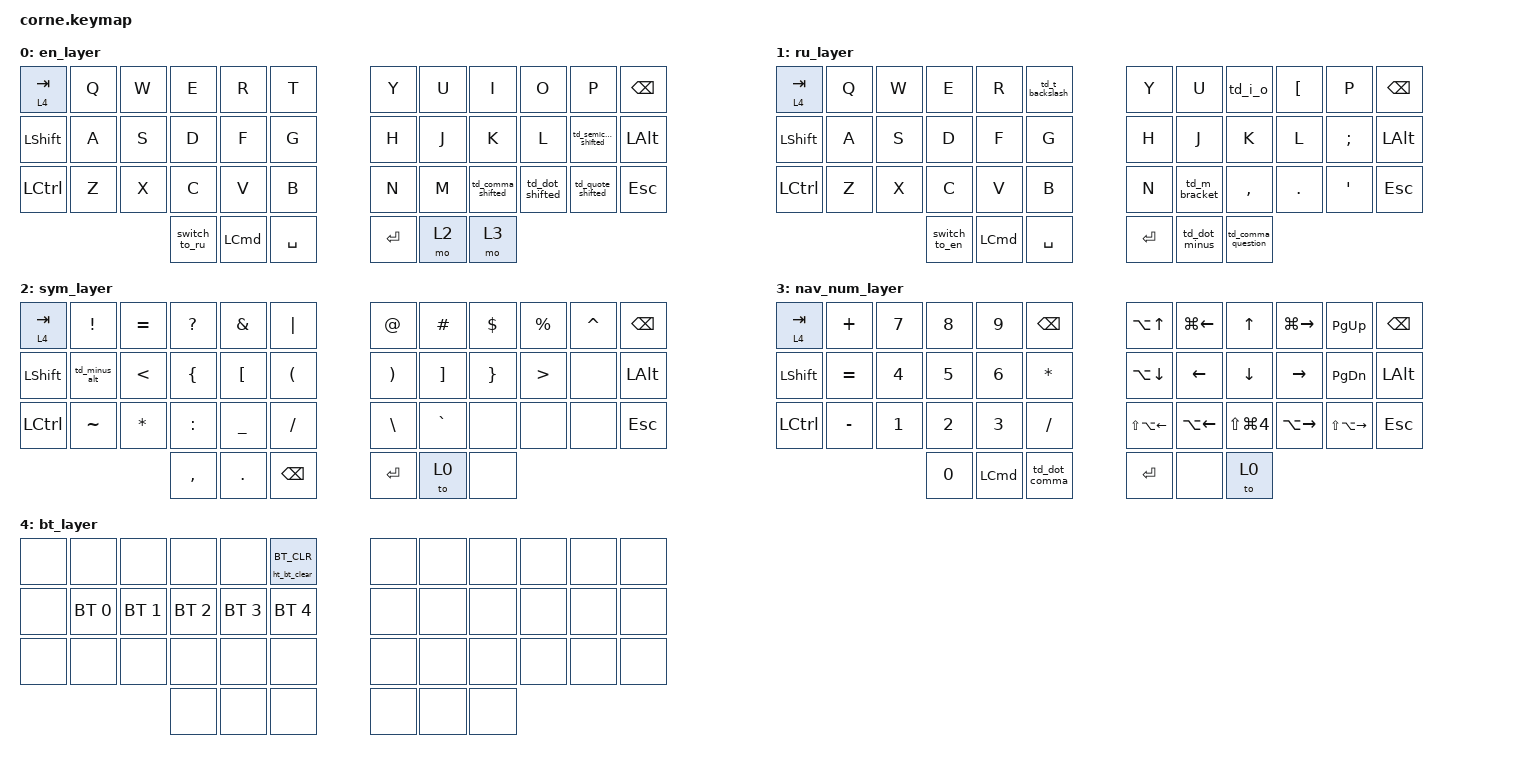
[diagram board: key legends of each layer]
/*
 * Copyright (c) 2020 The ZMK Contributors
 *
 * SPDX-License-Identifier: MIT
 */

#include <behaviors.dtsi>
#include <dt-bindings/zmk/bt.h>
#include <dt-bindings/zmk/keys.h>

/ {
    macros {
        switch_to_ru: switch_to_ru {
            compatible = "zmk,behavior-macro";
            #binding-cells = <0>;
            bindings = <&kp F18 &to 1>;
            label = "SWITCH_TO_RU";
        };

        switch_to_en: switch_to_en {
            compatible = "zmk,behavior-macro";
            #binding-cells = <0>;
            bindings = <&kp F17 &to 0>;
            label = "SWITCH_TO_EN";
        };
    };

    behaviors {
        td_m_bracket: td_m_bracket {
            compatible = "zmk,behavior-tap-dance";
            #binding-cells = <0>;
            bindings = <&kp M>, <&kp RIGHT_BRACKET>;
        };

        td_i_o: td_i_o {
            compatible = "zmk,behavior-tap-dance";
            #binding-cells = <0>;
            bindings = <&kp I>, <&kp O>;
        };

        td_t_backslash: td_t_backslash {
            compatible = "zmk,behavior-tap-dance";
            #binding-cells = <0>;
            bindings = <&kp T>, <&kp BACKSLASH>;
        };

        ht_tab_layer: ht_tab_layer {
            compatible = "zmk,behavior-hold-tap";
            bindings = <&mo>, <&kp>;

            #binding-cells = <2>;
            tapping-term-ms = <200>;
            flavor = "tap-preferred";
        };

        td_dot_comma: td_dot_comma {
            compatible = "zmk,behavior-tap-dance";
            #binding-cells = <0>;
            bindings = <&kp DOT>, <&kp COMMA>;
        };

        td_comma_shifted: td_comma_shifted {
            compatible = "zmk,behavior-tap-dance";
            #binding-cells = <0>;
            bindings = <&kp COMMA>, <&kp LS(COMMA)>;
        };

        td_dot_shifted: td_dot_shifted {
            compatible = "zmk,behavior-tap-dance";
            #binding-cells = <0>;
            bindings = <&kp DOT>, <&kp LS(DOT)>;
        };

        td_semicolon_shifted: td_semicolon_shifted {
            compatible = "zmk,behavior-tap-dance";
            #binding-cells = <0>;
            bindings = <&kp SEMI>, <&kp LS(SEMICOLON)>;
        };

        td_quote_shifted: td_quote_shifted {
            compatible = "zmk,behavior-tap-dance";
            #binding-cells = <0>;
            bindings = <&kp SINGLE_QUOTE>, <&kp LS(SINGLE_QUOTE)>;
        };

        ht_bt_clear: ht_bt_clear {
            compatible = "zmk,behavior-hold-tap";
            bindings = <&bt>, <&none>;

            #binding-cells = <2>;
            tapping-term-ms = <500>;
            flavor = "hold-preferred";
        };

        td_minus_alt: td_minus_alt {
            compatible = "zmk,behavior-tap-dance";
            #binding-cells = <0>;
            bindings = <&kp KP_MINUS>, <&kp LA(MINUS)>;
        };

        td_dot_minus: td_dot_minus {
            compatible = "zmk,behavior-tap-dance";
            #binding-cells = <0>;
            bindings = <&kp KP_DOT>, <&kp MINUS>;

            label = "TD_DOT_MINUS";
        };

        td_comma_question: td_comma_question {
            compatible = "zmk,behavior-tap-dance";
            #binding-cells = <0>;
            bindings = <&kp LS(KP_DOT)>, <&kp QUESTION>;

            label = "TD_COMMA_QUESTION";
        };
    };

    keymap {
        compatible = "zmk,keymap";

        en_layer {
            bindings = <
&ht_tab_layer 4 TAB  &kp Q  &kp W  &kp E          &kp R             &kp T        &kp Y      &kp U  &kp I              &kp O            &kp P                  &kp BSPC
&kp LEFT_SHIFT       &kp A  &kp S  &kp D          &kp F             &kp G        &kp H      &kp J  &kp K              &kp L            &td_semicolon_shifted  &kp LEFT_ALT
&kp LEFT_CONTROL     &kp Z  &kp X  &kp C          &kp V             &kp B        &kp N      &kp M  &td_comma_shifted  &td_dot_shifted  &td_quote_shifted      &kp ESCAPE
                                   &switch_to_ru  &kp LEFT_COMMAND  &kp SPACE    &kp ENTER  &mo 2  &mo 3
            >;
        };

        ru_layer {
            bindings = <
&ht_tab_layer 4 TAB  &kp Q  &kp W  &kp E          &kp R             &td_t_backslash    &kp Y      &kp U          &td_i_o             &kp LEFT_BRACKET  &kp P             &kp BACKSPACE
&kp LEFT_SHIFT       &kp A  &kp S  &kp D          &kp F             &kp G              &kp H      &kp J          &kp K               &kp L             &kp SEMICOLON     &kp LEFT_ALT
&kp LEFT_CONTROL     &kp Z  &kp X  &kp C          &kp V             &kp B              &kp N      &td_m_bracket  &kp COMMA           &kp DOT           &kp SINGLE_QUOTE  &kp ESCAPE
                                   &switch_to_en  &kp LEFT_COMMAND  &kp SPACE          &kp ENTER  &td_dot_minus  &td_comma_question
            >;
        };

        sym_layer {
            bindings = <
&ht_tab_layer 4 TAB  &kp EXCLAMATION  &kp EQUAL      &kp QUESTION    &kp AMPERSAND     &kp PIPE                &kp AT                 &kp HASH           &kp DOLLAR       &kp PERCENT       &kp CARET  &kp BSPC
&kp LEFT_SHIFT       &td_minus_alt    &kp LESS_THAN  &kp LEFT_BRACE  &kp LEFT_BRACKET  &kp LEFT_PARENTHESIS    &kp RIGHT_PARENTHESIS  &kp RIGHT_BRACKET  &kp RIGHT_BRACE  &kp GREATER_THAN  &none      &kp LEFT_ALT
&kp LEFT_CONTROL     &kp TILDE        &kp STAR       &kp COLON       &kp UNDERSCORE    &kp SLASH               &kp BACKSLASH          &kp GRAVE          &none            &none             &none      &kp ESCAPE
                                                     &kp COMMA       &kp DOT           &kp BACKSPACE           &kp RET                &to 0              &none
            >;
        };

        nav_num_layer {
            bindings = <
&ht_tab_layer 4 TAB  &kp PLUS   &kp NUMBER_7  &kp NUMBER_8  &kp NUMBER_9      &kp BACKSPACE    &kp LA(UP_ARROW)    &kp LG(LEFT)  &kp UP_ARROW          &kp LG(RIGHT)  &kp PAGE_UP        &kp BSPC
&kp LEFT_SHIFT       &kp EQUAL  &kp NUMBER_4  &kp NUMBER_5  &kp NUMBER_6      &kp ASTERISK     &kp LA(DOWN_ARROW)  &kp LEFT      &kp DOWN              &kp RIGHT      &kp PAGE_DOWN      &kp LEFT_ALT
&kp LEFT_CONTROL     &kp MINUS  &kp NUMBER_1  &kp NUMBER_2  &kp NUMBER_3      &kp SLASH        &kp LS(LA(LEFT))    &kp LA(LEFT)  &kp LS(LG(NUMBER_4))  &kp LA(RIGHT)  &kp LS(LA(RIGHT))  &kp ESCAPE
                                              &kp NUMBER_0  &kp LEFT_COMMAND  &td_dot_comma    &kp ENTER           &none         &to 0
            >;
        };

        bt_layer {
            bindings = <
&none  &none         &none         &none         &none         &ht_bt_clear BT_CLR      &none  &none  &none  &none  &none  &none
&none  &bt BT_SEL 0  &bt BT_SEL 1  &bt BT_SEL 2  &bt BT_SEL 3  &bt BT_SEL 4             &none  &none  &none  &none  &none  &none
&none  &none         &none         &none         &none         &none                    &none  &none  &none  &none  &none  &none
                                   &none         &none         &none                    &none  &none  &none
            >;
        };
    };
};
